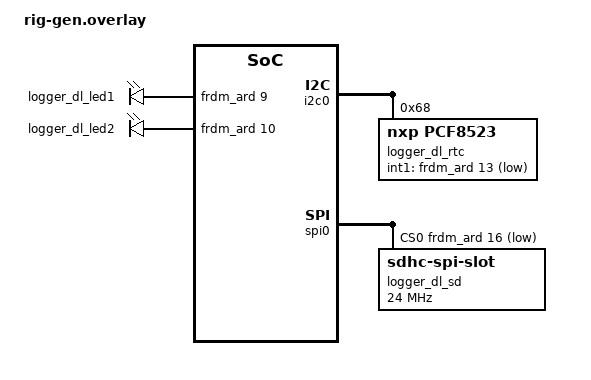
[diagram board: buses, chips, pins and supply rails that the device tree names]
/* generated by rigexp — do not edit; the rig file is the source of truth (R3)
 * rig: ard_datalogger  board: frdm_k64f/mk64f12/rig
 */

&i2c0 {
	logger_dl_rtc: rtc@68 {
		compatible = "nxp,pcf8523";
		alarms-count = <1>;
		battery-switch-over = "standard";
		reg = <0x68>;
		int1-gpios = <&frdm_ard 13 0x11>;	/* D7 */
		status = "okay";
	};
};

&spi0 {
	cs-gpios = <&frdm_ard 16 1 /* ACTIVE_LOW */>;
	logger_dl_sd: sdhc@0 {
		compatible = "zephyr,sdhc-spi-slot";
		spi-max-frequency = <24000000>;
		reg = <0>;
		status = "okay";
		sdmmc {
			compatible = "zephyr,sdmmc-disk";
			disk-name = "SD";
			status = "okay";
		};
	};
};

/ {
	gpio_leds: gpio_leds {
		compatible = "gpio-leds";
		logger_dl_led1: logger_dl_led1 {
			label = "logger_dl_led1";
			gpios = <&frdm_ard 9 0x0>;	/* D3 */
		};
		logger_dl_led2: logger_dl_led2 {
			label = "logger_dl_led2";
			gpios = <&frdm_ard 10 0x0>;	/* D4 */
		};
	};
};
